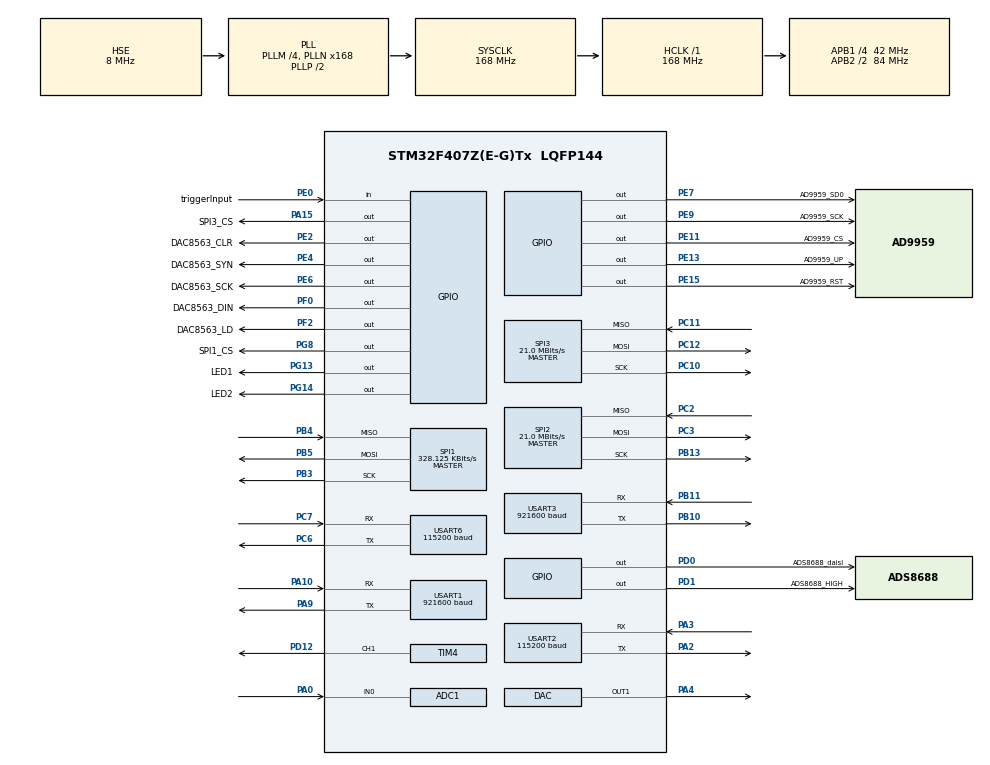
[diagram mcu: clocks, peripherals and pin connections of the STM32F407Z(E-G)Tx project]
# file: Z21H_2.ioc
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PH0-OSC_IN.Signal=RCC_OSC_IN
SPI3.Direction=SPI_DIRECTION_2LINES
SPI3.VirtualType=VM_MASTER
SPI1.VirtualType=VM_MASTER
SPI2.VirtualType=VM_MASTER
PB10.Mode=Asynchronous
PG8.Signal=GPIO_Output
PC12.Signal=SPI3_MOSI
Dma.SPI3_RX.2.Direction=DMA_PERIPH_TO_MEMORY
PB13.Signal=SPI2_SCK
PG13.Signal=GPIO_Output
PE6.GPIO_Label=DAC8563_SCK
RCC.SYSCLKSource=RCC_SYSCLKSOURCE_PLLCLK
USART3.BaudRate=921600
SPI1.Direction=SPI_DIRECTION_2LINES
RCC.APB2TimFreq_Value=168000000
Dma.ADC1.0.Direction=DMA_PERIPH_TO_MEMORY
PC7.Signal=USART6_RX
SPI1.CalculateBaudRate=328.125 KBits/s
PC3.Signal=SPI2_MOSI
PD0.Signal=GPIO_Output
Dma.ADC1.0.MemDataAlignment=DMA_MDATAALIGN_HALFWORD
PB3.Mode=Full_Duplex_Master
PD1.GPIO_Label=ADS8688_HIGH
DAC.DAC_Trigger=DAC_TRIGGER_T6_TRGO
PD1.GPIO_Speed=GPIO_SPEED_FREQ_MEDIUM
PE9.Signal=GPIO_Output
Dma.ADC1.0.PeriphInc=DMA_PINC_DISABLE
SPI1.DataSize=SPI_DATASIZE_8BIT
PE4.GPIO_Label=DAC8563_SYN
SPI2.CalculateBaudRate=21.0 MBits/s
PE2.Signal=GPIO_Output
Dma.DAC1.1.Priority=DMA_PRIORITY_LOW
Mcu.Package=LQFP144
SPI2.Mode=SPI_MODE_MASTER
SPI3.Mode=SPI_MODE_MASTER
PD12.Signal=S_TIM4_CH1
PA10.Signal=USART1_RX
PC11.Mode=Full_Duplex_Master
Dma.SPI3_RX.2.PeriphInc=DMA_PINC_DISABLE
PG8.GPIO_Speed=GPIO_SPEED_FREQ_HIGH
RCC.APB2CLKDivider=RCC_HCLK_DIV2
SH.S_TIM4_CH1.0=TIM4_CH1,PWM Generation1 CH1
RCC.APB1TimFreq_Value=84000000
Dma.ADC1.0.FIFOMode=DMA_FIFOMODE_DISABLE
PB13.Mode=Full_Duplex_Master
VP_TIM14_VS_ClockSourceINT.Mode=Enable_Timer
PE6.GPIO_Speed=GPIO_SPEED_FREQ_VERY_HIGH
Dma.SPI3_TX.3.Mode=DMA_NORMAL
Dma.ADC1.0.Instance=DMA2_Stream0
PE11.GPIO_Speed=GPIO_SPEED_FREQ_VERY_HIGH
PC6.Signal=USART6_TX
PC2.Signal=SPI2_MISO
PD1.Signal=GPIO_Output
SPI1.CLKPhase=SPI_PHASE_2EDGE
PD1.GPIO_PuPd=GPIO_PULLUP
RCC.APB1CLKDivider=RCC_HCLK_DIV4
PG13.GPIO_Label=LED1
USART2.BaudRate=115200
PA0-WKUP.Signal=ADCx_IN0
PD0.GPIO_Speed=GPIO_SPEED_FREQ_MEDIUM
PG8.GPIO_PuPd=GPIO_PULLUP
PA3.Mode=Asynchronous
PB11.Mode=Asynchronous
Dma.DAC1.1.Mode=DMA_CIRCULAR
PC6.Mode=Asynchronous
Dma.ADC1.0.Priority=DMA_PRIORITY_LOW
PA9.Signal=USART1_TX
PE9.GPIO_Label=AD9959_SCK
PB10.Signal=USART3_TX
PC12.Mode=Full_Duplex_Master
Dma.SPI3_TX.3.FIFOMode=DMA_FIFOMODE_DISABLE
NVIC.TIM3_IRQn=true\:3\:0\:true\:false\:true\:true\:false
VP_TIM13_VS_ClockSourceINT.Mode=Enable_Timer
Dma.SPI3_TX.3.Direction=DMA_MEMORY_TO_PERIPH
PE7.GPIO_Speed=GPIO_SPEED_FREQ_VERY_HIGH
PE15.Signal=GPIO_Output
SPI1.Mode=SPI_MODE_MASTER
ADC1.DMAContinuousRequests=ENABLE
PG14.GPIO_Label=LED2
Dma.DAC1.1.FIFOMode=DMA_FIFOMODE_DISABLE
TIM14.Prescaler=0
ADC1.SamplingTime-1\#ChannelRegularConversion=ADC_SAMPLETIME_3CYCLES
PA4.Signal=COMP_DAC1_group
PB5.Signal=SPI1_MOSI
ADC1.master=1
PE13.GPIO_Label=AD9959_UP
Dma.DAC1.1.Instance=DMA1_Stream5
USART1.VirtualMode=VM_ASYNC
ADC1.Rank-1\#ChannelRegularConversion=1
PD1.PinState=GPIO_PIN_SET
ProjectManager.HeapSize=0x200
VP_TIM4_VS_ClockSourceINT.Mode=Internal
NVIC.PriorityGroup=NVIC_PRIORITYGROUP_4
PE15.GPIO_Speed=GPIO_SPEED_FREQ_VERY_HIGH
PF0.GPIO_Label=DAC8563_DIN
Dma.SPI3_TX.3.Instance=DMA1_Stream7
Mcu.Family=STM32F4
NVIC.USART3_IRQn=true\:0\:0\:false\:false\:true\:true\:true
PC3.Mode=Full_Duplex_Master
RCC.CortexFreq_Value=168000000
Dma.SPI3_TX.3.MemDataAlignment=DMA_MDATAALIGN_HALFWORD
ADC1.ContinuousConvMode=ENABLE
PE11.GPIO_Label=AD9959_CS
USART1.BaudRate=921600
Dma.SPI3_RX.2.Instance=DMA1_Stream0
PC10.Signal=SPI3_SCK
Dma.DAC1.1.PeriphInc=DMA_PINC_DISABLE
PE2.GPIO_Speed=GPIO_SPEED_FREQ_VERY_HIGH
PD0.GPIO_Label=ADS8688_daisi
PE9.GPIO_Speed=GPIO_SPEED_FREQ_VERY_HIGH
PB11.Signal=USART3_RX
PF2.GPIO_Speed=GPIO_SPEED_FREQ_VERY_HIGH
Dma.SPI3_RX.2.PeriphDataAlignment=DMA_PDATAALIGN_HALFWORD
ProjectManager.StackSize=0x400
VP_TIM7_VS_ClockSourceINT.Mode=Enable_Timer
PA15.GPIO_Label=SPI3_CS
PG14.PinState=GPIO_PIN_SET
SPI1.CLKPolarity=SPI_POLARITY_HIGH
RCC.HCLKFreq_Value=168000000
TIM3.Period=13124
TIM7.Period=9999
RCC.AHBFreq_Value=168000000
PH0-OSC_IN.Mode=HSE-External-Oscillator
SPI3.DataSize=SPI_DATASIZE_16BIT
RCC.HSE_VALUE=8000000
Dma.SPI3_TX.3.PeriphInc=DMA_PINC_DISABLE
Dma.SPI3_TX.3.Priority=DMA_PRIORITY_VERY_HIGH
PB4.Mode=Full_Duplex_Master
PE13.Signal=GPIO_Output
PD0.PinState=GPIO_PIN_SET
PE4.GPIO_Speed=GPIO_SPEED_FREQ_VERY_HIGH
PB5.Mode=Full_Duplex_Master
Dma.DAC1.1.PeriphDataAlignment=DMA_PDATAALIGN_HALFWORD
SH.ADCx_IN0.0=ADC1_IN0,IN0
TIM6.Period=9
PE4.Signal=GPIO_Output
Dma.SPI3_RX.2.FIFOMode=DMA_FIFOMODE_DISABLE
NVIC.DMA1_Stream7_IRQn=true\:4\:0\:true\:false\:true\:true\:true
Dma.DAC1.1.Direction=DMA_MEMORY_TO_PERIPH
PH1-OSC_OUT.Mode=HSE-External-Oscillator
USART2.VirtualMode=VM_ASYNC
USART6.VirtualMode=VM_ASYNC
PA15.Signal=GPIO_Output
USART6.BaudRate=115200
PE0.GPIO_Label=triggerInput
Dma.SPI3_RX.2.Priority=DMA_PRIORITY_VERY_HIGH
PG8.PinState=GPIO_PIN_SET
Dma.Request2=SPI3_RX
Dma.Request1=DAC1
Dma.Request3=SPI3_TX
NVIC.DMA1_Stream0_IRQn=true\:4\:0\:true\:false\:true\:true\:true
PG13.GPIO_Speed=GPIO_SPEED_FREQ_HIGH
SPI2.Direction=SPI_DIRECTION_2LINES
PF0.Signal=GPIO_Output
PE7.Signal=GPIO_Output
SPI3.CRCCalculation=SPI_CRCCALCULATION_DISABLE
Dma.Request0=ADC1
SPI1.BaudRatePrescaler=SPI_BAUDRATEPRESCALER_256
Dma.DAC1.1.MemDataAlignment=DMA_MDATAALIGN_HALFWORD
PE2.GPIO_Label=DAC8563_CLR
NVIC.TIM7_IRQn=true\:2\:0\:true\:false\:true\:true\:false
VP_TIM3_VS_ClockSourceINT.Mode=Internal
PB4.Signal=SPI1_MISO
PA3.Signal=USART2_RX
PE0.GPIO_PuPd=GPIO_PULLDOWN
Dma.SPI3_TX.3.MemInc=DMA_MINC_ENABLE
RCC.PLLSourceVirtual=RCC_PLLSOURCE_HSE
TIM4.Channel-PWM\ Generation1\ CH1=TIM_CHANNEL_1
SH.COMP_DAC1_group.0=DAC_OUT1,DAC_OUT1
PA10.Mode=Asynchronous
PC11.Signal=SPI3_MISO
TIM6.Prescaler=83
PC10.Mode=Full_Duplex_Master
VP_TIM6_VS_ClockSourceINT.Mode=Enable_Timer
PC2.Mode=Full_Duplex_Master
NVIC.USART2_IRQn=true\:0\:0\:false\:false\:true\:true\:true
NVIC.USART6_IRQn=true\:1\:0\:true\:false\:true\:true\:true
PF0.GPIO_Speed=GPIO_SPEED_FREQ_VERY_HIGH
Dma.DAC1.1.MemInc=DMA_MINC_ENABLE
PG8.GPIO_Label=SPI1_CS
Dma.ADC1.0.PeriphDataAlignment=DMA_PDATAALIGN_HALFWORD
PA9.Mode=Asynchronous
PE15.GPIO_Label=AD9959_RST
ProjectManager.TargetToolchain=STM32CubeIDE
Dma.ADC1.0.Mode=DMA_CIRCULAR
ADC1.Channel-1\#ChannelRegularConversion=ADC_CHANNEL_0
PF2.Signal=GPIO_Output
PE11.Signal=GPIO_Output
RCC.LSE_VALUE=32768
PG14.Signal=GPIO_Output
TIM7.Prescaler=8399
board=custom
SPI3.CLKPhase=SPI_PHASE_2EDGE
RCC.VCOOutputFreq_Value=336000000
PA15.PinState=GPIO_PIN_SET
RCC.APB2Freq_Value=84000000
SPI3.CalculateBaudRate=21.0 MBits/s
VP_TIM2_VS_ClockSourceINT.Mode=Internal
SPI3.BaudRatePrescaler=SPI_BAUDRATEPRESCALER_2
Dma.SPI3_TX.3.PeriphDataAlignment=DMA_PDATAALIGN_HALFWORD
TIM6.TIM_MasterOutputTrigger=TIM_TRGO_UPDATE
PH1-OSC_OUT.Signal=RCC_OSC_OUT
PE6.Signal=GPIO_Output
Dma.SPI3_RX.2.Mode=DMA_NORMAL
Mcu.Name=STM32F407Z(E-G)Tx
PE0.Signal=GPIO_Input
PE7.GPIO_Label=AD9959_SD0
PA2.Signal=USART2_TX
RCC.48MHZClocksFreq_Value=84000000
PB3.Signal=SPI1_SCK
RCC.SYSCLKFreq_VALUE=168000000
USART3.VirtualMode=VM_ASYNC
Dma.SPI3_RX.2.MemInc=DMA_MINC_ENABLE
PA15.GPIO_Speed=GPIO_SPEED_FREQ_VERY_HIGH
Dma.ADC1.0.MemInc=DMA_MINC_ENABLE
RCC.HSI_VALUE=16000000
ADC1.NbrOfConversionFlag=1
RCC.PLLM=4
RCC.PLLN=168
PE13.GPIO_Speed=GPIO_SPEED_FREQ_VERY_HIGH
PA2.Mode=Asynchronous
PC7.Mode=Asynchronous
Dma.SPI3_RX.2.MemDataAlignment=DMA_MDATAALIGN_HALFWORD
RCC.APB1Freq_Value=42000000
PG14.GPIO_Speed=GPIO_SPEED_FREQ_HIGH
PF2.GPIO_Label=DAC8563_LD

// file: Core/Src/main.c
/* USER CODE BEGIN Header */
/**
  ******************************************************************************
  * @file           : main.c
  * @brief          : Main program body
  ******************************************************************************
  * @attention
  *
  * <h2><center>&copy; Copyright (c) 2021 STMicroelectronics.
  * All rights reserved.</center></h2>
  *
  * This software component is licensed by ST under BSD 3-Clause license,
  * the "License"; You may not use this file except in compliance with the
  * License. You may obtain a copy of the License at:
  *                        opensource.org/licenses/BSD-3-Clause
  *
  ******************************************************************************
  */
/* USER CODE END Header */
#include "main.h"
#include "adc.h"
#include "dac.h"
#include "dma.h"
#include "spi.h"
#include "tim.h"
#include "usart.h"
#include "gpio.h"

/* USER CODE BEGIN Includes */
#include "stdio.h"
/* USER CODE END Includes */

void SystemClock_Config(void);

int main(void)
{

  /* MCU Configuration--------------------------------------------------------*/

  /* Reset of all peripherals, Initializes the Flash interface and the Systick. */
  HAL_Init();

  /* Configure the system clock */
  SystemClock_Config();

  /* Initialize all configured peripherals */
  MX_GPIO_Init();
  MX_DMA_Init();
  MX_SPI3_Init();
  MX_TIM7_Init();
  MX_USART1_UART_Init();
  MX_USART2_UART_Init();
  MX_USART3_UART_Init();
  MX_USART6_UART_Init();
  MX_SPI1_Init();
  MX_TIM3_Init();
  MX_ADC1_Init();
  MX_DAC_Init();
  MX_TIM6_Init();
  MX_TIM2_Init();
  MX_TIM14_Init();
  MX_SPI2_Init();
  MX_TIM13_Init();
  MX_TIM4_Init();
  /* USER CODE BEGIN 2 */

  init_start();

  /* USER CODE END 2 */

  /* Infinite loop */
  /* USER CODE BEGIN WHILE */
  while (1)
  {
	  while_do();
    /* USER CODE END WHILE */

  }
}

void SystemClock_Config(void)
{
  RCC_OscInitTypeDef RCC_OscInitStruct = {0};
  RCC_ClkInitTypeDef RCC_ClkInitStruct = {0};

  /** Configure the main internal regulator output voltage
  */
  __HAL_RCC_PWR_CLK_ENABLE();
  __HAL_PWR_VOLTAGESCALING_CONFIG(PWR_REGULATOR_VOLTAGE_SCALE1);
  /** Initializes the RCC Oscillators according to the specified parameters
  * in the RCC_OscInitTypeDef structure.
  */
  RCC_OscInitStruct.OscillatorType = RCC_OSCILLATORTYPE_HSE;
  RCC_OscInitStruct.HSEState = RCC_HSE_ON;
  RCC_OscInitStruct.PLL.PLLState = RCC_PLL_ON;
  RCC_OscInitStruct.PLL.PLLSource = RCC_PLLSOURCE_HSE;
  RCC_OscInitStruct.PLL.PLLM = 4;
  RCC_OscInitStruct.PLL.PLLN = 168;
  RCC_OscInitStruct.PLL.PLLP = RCC_PLLP_DIV2;
  RCC_OscInitStruct.PLL.PLLQ = 4;
  if (HAL_RCC_OscConfig(&RCC_OscInitStruct) != HAL_OK)
  {
    Error_Handler();
  }
  /** Initializes the CPU, AHB and APB buses clocks
  */
  RCC_ClkInitStruct.ClockType = RCC_CLOCKTYPE_HCLK|RCC_CLOCKTYPE_SYSCLK
                              |RCC_CLOCKTYPE_PCLK1|RCC_CLOCKTYPE_PCLK2;
  RCC_ClkInitStruct.SYSCLKSource = RCC_SYSCLKSOURCE_PLLCLK;
  RCC_ClkInitStruct.AHBCLKDivider = RCC_SYSCLK_DIV1;
  RCC_ClkInitStruct.APB1CLKDivider = RCC_HCLK_DIV4;
  RCC_ClkInitStruct.APB2CLKDivider = RCC_HCLK_DIV2;

  if (HAL_RCC_ClockConfig(&RCC_ClkInitStruct, FLASH_LATENCY_5) != HAL_OK)
  {
    Error_Handler();
  }
}

void Error_Handler(void)
{
  __disable_irq();
  while (1)
  {
  }
}

/************************ (C) COPYRIGHT STMicroelectronics *****END OF FILE****/
